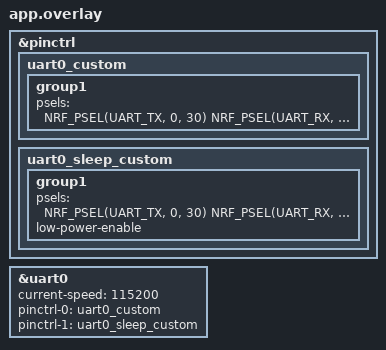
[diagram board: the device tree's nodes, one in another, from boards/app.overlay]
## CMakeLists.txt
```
cmake_minimum_required(VERSION 3.20.0)
find_package(Zephyr REQUIRED HINTS $ENV{ZEPHYR_BASE})

project(fth_uart1)

target_sources(app PRIVATE src/main.c)
```

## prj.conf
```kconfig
CONFIG_SERIAL=y
CONFIG_UART_INTERRUPT_DRIVEN=n

CONFIG_CLOCK_CONTROL_NRF_K32SRC_RC=y
```

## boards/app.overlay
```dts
&pinctrl {
    uart0_custom: uart0_custom {
        group1 {
            psels = <
                NRF_PSEL(UART_TX, 0, 30)
                NRF_PSEL(UART_RX, 0, 31)
            >;
        };
    };

    uart0_sleep_custom: uart0_sleep_custom {
        group1 {
            psels = <
                NRF_PSEL(UART_TX, 0, 30)
                NRF_PSEL(UART_RX, 0, 31)
            >;
            low-power-enable;
        };
    };
};

&uart0 {
    status = "okay";
    current-speed = <115200>;

    pinctrl-0 = <&uart0_custom>;
    pinctrl-1 = <&uart0_sleep_custom>;
    pinctrl-names = "default", "sleep";
};
```

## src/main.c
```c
#include <zephyr/kernel.h>
#include <zephyr/device.h>
#include <zephyr/drivers/uart.h>

#define UART_NODE DT_NODELABEL(uart0)

static const struct device *uart_dev = DEVICE_DT_GET(UART_NODE);

int main(void)
{
    const char msg[] = "Merhaba dunya\r\n";

    if (!device_is_ready(uart_dev)) {
        return 0;
    }

    while (1) {
        for (int i = 0; msg[i] != '\0'; i++) {
            uart_poll_out(uart_dev, msg[i]);
        }

        k_msleep(1000);
    }
}
```
